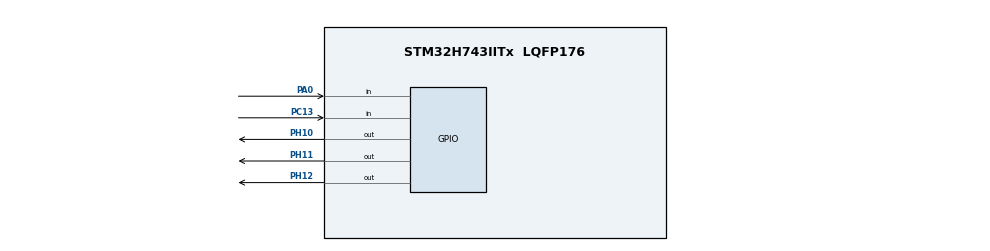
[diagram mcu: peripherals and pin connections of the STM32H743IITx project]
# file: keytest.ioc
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Mcu.Family=STM32H7
Mcu.Name=STM32H743IITx
Mcu.Package=LQFP176
NVIC.PriorityGroup=NVIC_PRIORITYGROUP_4
PA0.Signal=GPIO_Input
PC13.Signal=GPIO_Input
PH0-OSC_IN\ (PH0).Mode=HSE-External-Oscillator
PH0-OSC_IN\ (PH0).Signal=RCC_OSC_IN
PH1-OSC_OUT\ (PH1).Mode=HSE-External-Oscillator
PH1-OSC_OUT\ (PH1).Signal=RCC_OSC_OUT
PH10.Signal=GPIO_Output
PH11.Signal=GPIO_Output
PH12.Signal=GPIO_Output
ProjectManager.HeapSize=0x200
ProjectManager.StackSize=0x400
ProjectManager.TargetToolchain=MDK-ARM V5.27
RCC.ADCFreq_Value=129000000
RCC.APB1Freq_Value=64000000
RCC.APB2Freq_Value=64000000
RCC.APB3Freq_Value=64000000
RCC.APB4Freq_Value=64000000
RCC.CortexFreq_Value=64000000
RCC.HCLKFreq_Value=64000000
RCC.SYSCLKFreq_VALUE=64000000
RCC.USBFreq_Value=129000000
board=custom

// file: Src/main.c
/* USER CODE BEGIN Header */
/**
  ******************************************************************************
  * @file           : main.c
  * @brief          : Main program body
  ******************************************************************************
  * @attention
  *
  * <h2><center>&copy; Copyright (c) 2020 STMicroelectronics.
  * All rights reserved.</center></h2>
  *
  * This software component is licensed by ST under BSD 3-Clause license,
  * the "License"; You may not use this file except in compliance with the
  * License. You may obtain a copy of the License at:
  *                        opensource.org/licenses/BSD-3-Clause
  *
  ******************************************************************************
  */
/* USER CODE END Header */

#include "main.h"
#include "gpio.h"
#include "key.h"

void SystemClock_Config(void);

int main(void)
{

  /* MCU Configuration--------------------------------------------------------*/

  /* Reset of all peripherals, Initializes the Flash interface and the Systick. */
  HAL_Init();

  /* Configure the system clock */
  SystemClock_Config();

  /* Initialize all configured peripherals */
  MX_GPIO_Init();

  /* Infinite loop */
  while (1)
  {

    /* USER CODE BEGIN 3 */
			if( Key_Scan(KEY1_GPIO_PORT,KEY1_PIN) == KEY_ON  )
		{
			/*LED1��ת*/
			HAL_GPIO_TogglePin(GPIOH,GPIO_PIN_10);
		}

    if( Key_Scan(KEY2_GPIO_PORT,KEY2_PIN) == KEY_ON  )
		{
			/*LED2��ת*/
			HAL_GPIO_TogglePin(GPIOH,GPIO_PIN_11);
		}
  }
  /* USER CODE END 3 */
}

void SystemClock_Config(void)
{
  RCC_OscInitTypeDef RCC_OscInitStruct = {0};
  RCC_ClkInitTypeDef RCC_ClkInitStruct = {0};

  /** Supply configuration update enable
  */
  HAL_PWREx_ConfigSupply(PWR_LDO_SUPPLY);
  /** Configure the main internal regulator output voltage
  */
  __HAL_PWR_VOLTAGESCALING_CONFIG(PWR_REGULATOR_VOLTAGE_SCALE3);

  while(!__HAL_PWR_GET_FLAG(PWR_FLAG_VOSRDY)) {}
  /** Initializes the CPU, AHB and APB busses clocks
  */
  RCC_OscInitStruct.OscillatorType = RCC_OSCILLATORTYPE_HSI;
  RCC_OscInitStruct.HSIState = RCC_HSI_DIV1;
  RCC_OscInitStruct.HSICalibrationValue = RCC_HSICALIBRATION_DEFAULT;
  RCC_OscInitStruct.PLL.PLLState = RCC_PLL_NONE;
  if (HAL_RCC_OscConfig(&RCC_OscInitStruct) != HAL_OK)
  {
    Error_Handler();
  }
  /** Initializes the CPU, AHB and APB busses clocks
  */
  RCC_ClkInitStruct.ClockType = RCC_CLOCKTYPE_HCLK|RCC_CLOCKTYPE_SYSCLK
                              |RCC_CLOCKTYPE_PCLK1|RCC_CLOCKTYPE_PCLK2
                              |RCC_CLOCKTYPE_D3PCLK1|RCC_CLOCKTYPE_D1PCLK1;
  RCC_ClkInitStruct.SYSCLKSource = RCC_SYSCLKSOURCE_HSI;
  RCC_ClkInitStruct.SYSCLKDivider = RCC_SYSCLK_DIV1;
  RCC_ClkInitStruct.AHBCLKDivider = RCC_HCLK_DIV1;
  RCC_ClkInitStruct.APB3CLKDivider = RCC_APB3_DIV1;
  RCC_ClkInitStruct.APB1CLKDivider = RCC_APB1_DIV1;
  RCC_ClkInitStruct.APB2CLKDivider = RCC_APB2_DIV1;
  RCC_ClkInitStruct.APB4CLKDivider = RCC_APB4_DIV1;

  if (HAL_RCC_ClockConfig(&RCC_ClkInitStruct, FLASH_LATENCY_0) != HAL_OK)
  {
    Error_Handler();
  }
}

void Error_Handler(void)
{
}

/************************ (C) COPYRIGHT STMicroelectronics *****END OF FILE****/
